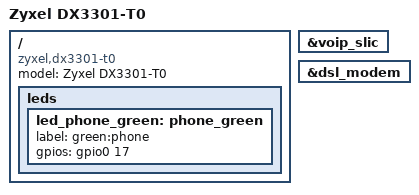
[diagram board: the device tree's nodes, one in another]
// SPDX-License-Identifier: (GPL-2.0-only OR BSD-2-Clause)
/*
 * Copyright (C) 2026 Alan <alan@Riffraff>
 * Copyright (C) 2026 OpenWrt.org
 *
 * ============================================================================
 * LEAF NODE PROFILE: ZYXEL DX3301-T0 HIGH-TIER INTEGRATED GATEWAY
 * ============================================================================
 * Subseries Inheritance: 3301 Wi-Fi 6 Platform Blueprint (Native USB 3.0 Active)
 * RAM Configuration: 512MB High-Capacity Allocation
 * Fleet Relationship Matrix:
 *  - vs DX3300: DX3301 introduces uncompromised SuperSpeed storage options.
 *  - vs EX3301: DX3301 fires upstream connections over integrated VDSL2 vectoring.
 */

/dts-v1/;
#include "en751627_zyxel_3301_subseries.dtsi"

/ {
	model = "Zyxel DX3301-T0";
	compatible = "zyxel,dx3301-t0", "econet,en751627";

	leds {
		led_phone_green: phone_green {
			label = "green:phone";
			gpios = <&gpio0 17 GPIO_ACTIVE_HIGH>;
		};
	};
};

&voip_slic {
	status = "okay"; /* Activate open-ended VoIP SLIC hooks */
};

&dsl_modem {
	status = "okay"; /* Enable integrated VDSL layer routing loops */
};
